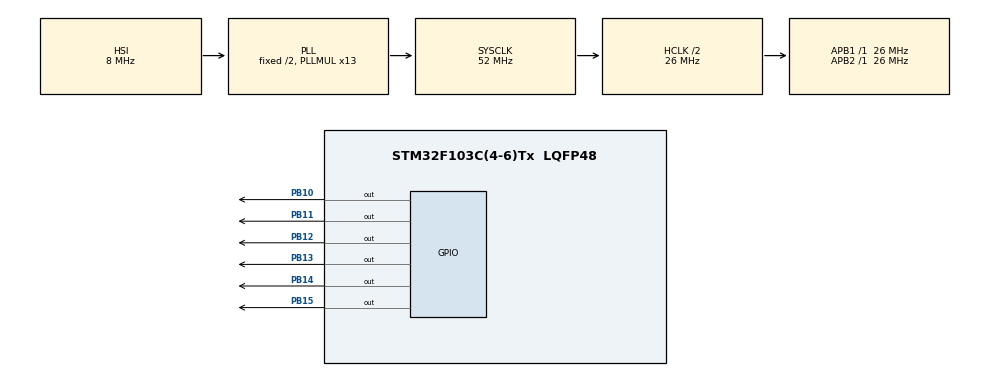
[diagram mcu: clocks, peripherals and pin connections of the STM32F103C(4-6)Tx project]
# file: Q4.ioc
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Mcu.Family=STM32F1
Mcu.Name=STM32F103C(4-6)Tx
Mcu.Package=LQFP48
NVIC.PriorityGroup=NVIC_PRIORITYGROUP_4
PB10.Signal=GPIO_Output
PB11.Signal=GPIO_Output
PB12.Signal=GPIO_Output
PB13.Signal=GPIO_Output
PB14.Signal=GPIO_Output
PB15.Signal=GPIO_Output
ProjectManager.HeapSize=0x200
ProjectManager.StackSize=0x400
ProjectManager.TargetToolchain=STM32CubeIDE
RCC.AHBCLKDivider=RCC_SYSCLK_DIV2
RCC.AHBFreq_Value=26000000
RCC.APB1Freq_Value=26000000
RCC.APB1TimFreq_Value=26000000
RCC.APB2Freq_Value=26000000
RCC.APB2TimFreq_Value=26000000
RCC.HCLKFreq_Value=26000000
RCC.PLLMUL=RCC_PLL_MUL13
RCC.SYSCLKFreq_VALUE=52000000
RCC.SYSCLKSource=RCC_SYSCLKSOURCE_PLLCLK
RCC.USBFreq_Value=52000000
VP_SYS_VS_ND.Mode=No_Debug
board=custom

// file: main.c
/* USER CODE BEGIN Header */
/**
  ******************************************************************************
  * @file           : main.c
  * @brief          : Main program body
  ******************************************************************************
  * @attention
  *
  * Copyright (c) 2023 STMicroelectronics.
  * All rights reserved.
  *
  * This software is licensed under terms that can be found in the LICENSE file
  * in the root directory of this software component.
  * If no LICENSE file comes with this software, it is provided AS-IS.
  *
  ******************************************************************************
  */
/* USER CODE END Header */
#include "main.h"

/* USER CODE BEGIN Includes */
#include "lcd_txt.h"
/* USER CODE END Includes */

void SystemClock_Config(void);
static void MX_GPIO_Init(void);

int main(void)
{
  /* USER CODE BEGIN 1 */
int i,j=0;
char buffer[30];
  /* USER CODE END 1 */

  /* MCU Configuration--------------------------------------------------------*/

  /* Reset of all peripherals, Initializes the Flash interface and the Systick. */
  HAL_Init();

  /* Configure the system clock */
  SystemClock_Config();

  /* Initialize all configured peripherals */
  MX_GPIO_Init();
  /* USER CODE BEGIN 2 */
  lcd_init();
  lcd_clear();
  /* USER CODE END 2 */

  /* Infinite loop */
  /* USER CODE BEGIN WHILE */
  while (1)
  {
	  i = sprintf(buffer,"%d\n", j);
	  lcd_puts(0,0,(int8_t*)buffer);
	  j = j+1;
	  HAL_Delay(50);
	  if (j == 50)
		  j = 0;
	  //i += sprintf(buffer+i,"%d\n", j+1);
    /* USER CODE END WHILE */

  }
}

void SystemClock_Config(void)
{
  RCC_OscInitTypeDef RCC_OscInitStruct = {0};
  RCC_ClkInitTypeDef RCC_ClkInitStruct = {0};

  /** Initializes the RCC Oscillators according to the specified parameters
  * in the RCC_OscInitTypeDef structure.
  */
  RCC_OscInitStruct.OscillatorType = RCC_OSCILLATORTYPE_HSI;
  RCC_OscInitStruct.HSIState = RCC_HSI_ON;
  RCC_OscInitStruct.HSICalibrationValue = RCC_HSICALIBRATION_DEFAULT;
  RCC_OscInitStruct.PLL.PLLState = RCC_PLL_ON;
  RCC_OscInitStruct.PLL.PLLSource = RCC_PLLSOURCE_HSI_DIV2;
  RCC_OscInitStruct.PLL.PLLMUL = RCC_PLL_MUL13;
  if (HAL_RCC_OscConfig(&RCC_OscInitStruct) != HAL_OK)
  {
    Error_Handler();
  }

  /** Initializes the CPU, AHB and APB buses clocks
  */
  RCC_ClkInitStruct.ClockType = RCC_CLOCKTYPE_HCLK|RCC_CLOCKTYPE_SYSCLK
                              |RCC_CLOCKTYPE_PCLK1|RCC_CLOCKTYPE_PCLK2;
  RCC_ClkInitStruct.SYSCLKSource = RCC_SYSCLKSOURCE_PLLCLK;
  RCC_ClkInitStruct.AHBCLKDivider = RCC_SYSCLK_DIV2;
  RCC_ClkInitStruct.APB1CLKDivider = RCC_HCLK_DIV1;
  RCC_ClkInitStruct.APB2CLKDivider = RCC_HCLK_DIV1;

  if (HAL_RCC_ClockConfig(&RCC_ClkInitStruct, FLASH_LATENCY_2) != HAL_OK)
  {
    Error_Handler();
  }
}

static void MX_GPIO_Init(void)
{
  GPIO_InitTypeDef GPIO_InitStruct = {0};

  /* GPIO Ports Clock Enable */
  __HAL_RCC_GPIOB_CLK_ENABLE();

  /*Configure GPIO pin Output Level */
  HAL_GPIO_WritePin(GPIOB, GPIO_PIN_10|GPIO_PIN_11|GPIO_PIN_12|GPIO_PIN_13
                          |GPIO_PIN_14|GPIO_PIN_15, GPIO_PIN_RESET);

  /*Configure GPIO pins : PB10 PB11 PB12 PB13
                           PB14 PB15 */
  GPIO_InitStruct.Pin = GPIO_PIN_10|GPIO_PIN_11|GPIO_PIN_12|GPIO_PIN_13
                          |GPIO_PIN_14|GPIO_PIN_15;
  GPIO_InitStruct.Mode = GPIO_MODE_OUTPUT_PP;
  GPIO_InitStruct.Pull = GPIO_NOPULL;
  GPIO_InitStruct.Speed = GPIO_SPEED_FREQ_LOW;
  HAL_GPIO_Init(GPIOB, &GPIO_InitStruct);

}

void Error_Handler(void)
{
  __disable_irq();
  while (1)
  {
  }
}
